/*
 * The MIT License (MIT)
 *
 * Copyright (c) 2015-2019 Erik Moqvist
 *
 * Permission is hereby granted, free of charge, to any person obtaining a copy
 * of this software and associated documentation files (the "Software"), to deal
 * in the Software without restriction, including without limitation the rights
 * to use, copy, modify, merge, publish, distribute, sublicense, and/or sell
 * copies of the Software, and to permit persons to whom the Software is
 * furnished to do so, subject to the following conditions:
 *
 * The above copyright notice and this permission notice shall be included in all
 * copies or substantial portions of the Software.
 *
 * THE SOFTWARE IS PROVIDED "AS IS", WITHOUT WARRANTY OF ANY KIND, EXPRESS OR
 * IMPLIED, INCLUDING BUT NOT LIMITED TO THE WARRANTIES OF MERCHANTABILITY,
 * FITNESS FOR A PARTICULAR PURPOSE AND NONINFRINGEMENT. IN NO EVENT SHALL THE
 * AUTHORS OR COPYRIGHT HOLDERS BE LIABLE FOR ANY CLAIM, DAMAGES OR OTHER
 * LIABILITY, WHETHER IN AN ACTION OF CONTRACT, TORT OR OTHERWISE, ARISING FROM,
 * OUT OF OR IN CONNECTION WITH THE SOFTWARE OR THE USE OR OTHER DEALINGS IN THE
 * SOFTWARE.
 */

VERSION ""

NS_ :

BS_:

BU_: GMLAN NEO
VAL_TABLE_ GearShifter 3 "Park" 0 "Drive/Low" ;
VAL_TABLE_ DriverDoorStatus 1 "Opened" 0 "Closed" ;
VAL_TABLE_ LKAGapButton 2 "???" 1 "??" 0 "None" ;
VAL_TABLE_ CruiseButtons 6 "Cancel" 5 "Main" 3 "Set" 2 "Resume" 1 "None" ;
VAL_TABLE_ CruiseControlActive 1 "Active" 0 "Inactive" ;
VAL_TABLE_ BlinkerStatus 1 "Active" 0 "Inactive" ;

BO_ 4294967295 DriverDoorStatus: 1 GMLAN
 SG_ DriverDoorOpened : 0|1@0+ (1,0) [0|0] ""  NEO

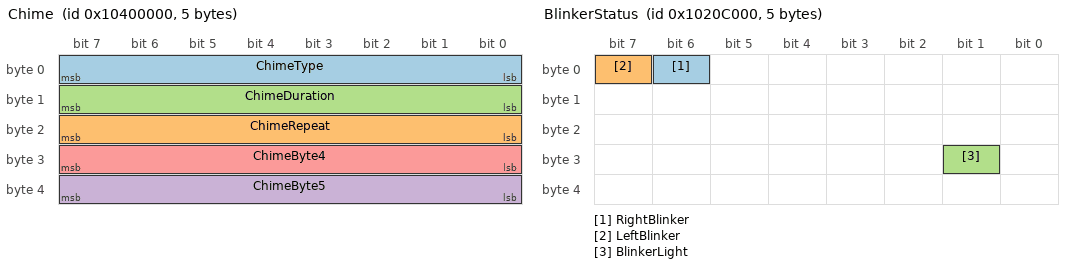
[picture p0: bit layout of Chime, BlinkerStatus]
BO_ 272629760 Chime: 5 NEO
 SG_ ChimeType : 7|8@0+ (1,0) [0|0] ""  GMLAN
 SG_ ChimeRepeat : 23|8@0+ (1,0) [0|0] ""  GMLAN
 SG_ ChimeDuration : 15|8@0+ (1,0) [0|0] ""  GMLAN
 SG_ ChimeByte5 : 39|8@0+ (1,0) [0|0] ""  GMLAN
 SG_ ChimeByte4 : 31|8@0+ (1,0) [0|0] ""  GMLAN

BO_ 270581760 BlinkerStatus: 5 GMLAN
 SG_ RightBlinker : 6|1@0+ (1,0) [0|0] ""  NEO
 SG_ LeftBlinker : 7|1@0+ (1,0) [0|0] ""  NEO
 SG_ BlinkerLight : 25|1@0+ (1,0) [0|0] ""  NEO

BO_ 270794752 SteeringWheelAngle: 8 GMLAN
 SG_ SteeringWheelAngle : 39|16@0- (0.0625,0) [-540|540] "deg"  NEO

BO_ 271368192 GearShifter: 8 GMLAN
 SG_ GearShifter : 17|2@0+ (1,0) [0|3] ""  NEO

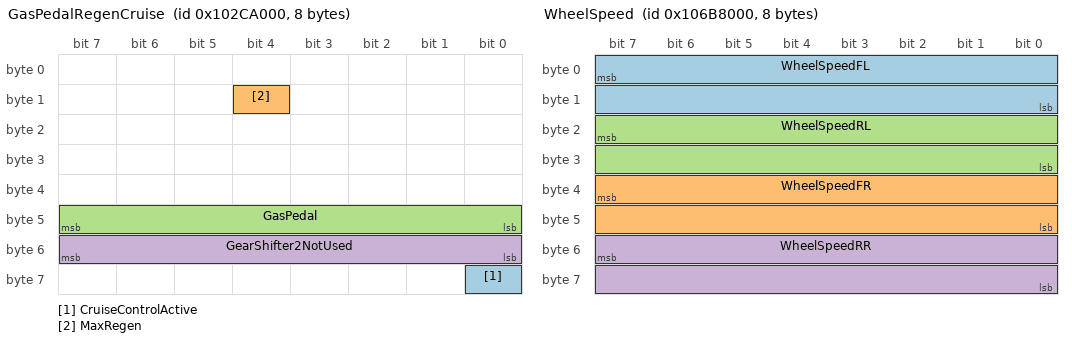
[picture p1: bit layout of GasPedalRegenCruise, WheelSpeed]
BO_ 271360000 GasPedalRegenCruise: 8 GMLAN
 SG_ CruiseControlActive : 56|1@0+ (1,0) [0|0] ""  GMLAN
 SG_ MaxRegen : 12|1@0+ (1,0) [0|1] ""  GMLAN,NEO
 SG_ GasPedal : 47|8@0+ (1,0) [0|254] ""  GMLAN,NEO
 SG_ GearShifter2NotUsed : 55|8@0+ (1,0) [0|255] ""  GMLAN,NEO

BO_ 270860288 BrakePedal: 2 GMLAN
 SG_ BrakeLevel : 2|2@0+ (1,0) [0|3] ""  NEO
 SG_ BrakeSensor : 15|8@0+ (1,0) [0|255] ""  NEO

BO_ 275480576 WheelSpeed: 8 GMLAN
 SG_ WheelSpeedFL : 7|16@0+ (0.01,0) [0|70] "yd/s"  NEO
 SG_ WheelSpeedFR : 39|16@0+ (0.01,0) [0|70] "yd/s"  NEO
 SG_ WheelSpeedRL : 23|16@0+ (0.01,0) [0|70] "yd/s"  NEO
 SG_ WheelSpeedRR : 55|16@0+ (0.01,0) [0|70] "yd/s"  NEO

BO_ 270598144 VehicleSpeed: 8 GMLAN
 SG_ VehicleSpeed1 : 7|16@0+ (0.01,0) [0|100] "mph"  NEO
 SG_ VehicleSpeed2 : 39|16@0+ (0.01,0) [0|100] "mph"  NEO

BO_ 276135936 CruiseButtons: 3 GMLAN
 SG_ CruiseButtons : 3|3@0+ (1,0) [0|12] ""  NEO

BO_ 276127744 CruiseButtons2: 1 GMLAN
 SG_ LKAGapButton : 1|2@0+ (1,0) [0|2] ""  NEO

BA_DEF_  "UseGMParameterIDs" INT 0 0;
BA_DEF_  "ProtocolType" STRING ;
BA_DEF_  "BusType" STRING ;
BA_DEF_DEF_  "UseGMParameterIDs" 1;
BA_DEF_DEF_  "ProtocolType" "GMLAN";
BA_DEF_DEF_  "BusType" "";
BA_ "BusType" "CAN";
VAL_ 4294967295 DriverDoorOpened 1 "Opened" 0 "Closed" ;
VAL_ 270581760 RightBlinker 1 "Active" 0 "Inactive" ;
VAL_ 270581760 LeftBlinker 1 "Active" 0 "Inactive" ;
VAL_ 270581760 BlinkerLight 1 "Active" 0 "Inactive" ;
VAL_ 271368192 GearShifter 3 "Park" 0 "Drive/Low" ;
VAL_ 271360000 CruiseControlActive 1 "Active" 0 "Inactive" ;
VAL_ 276135936 CruiseButtons 6 "Cancel" 5 "Main" 3 "Set" 2 "Resume" 1 "None" ;
VAL_ 276127744 LKAGapButton 2 "???" 1 "??" 0 "None" ;
